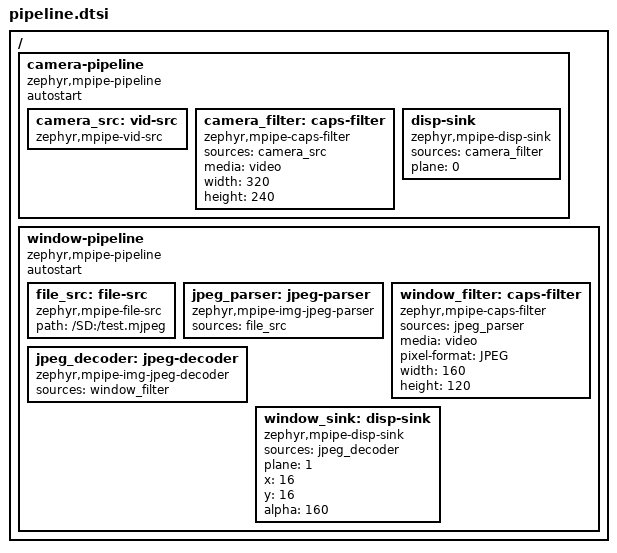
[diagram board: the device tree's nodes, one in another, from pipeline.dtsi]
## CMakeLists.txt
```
# Copyright 2026 NXP
# SPDX-License-Identifier: Apache-2.0

cmake_minimum_required(VERSION 3.20.0)
find_package(Zephyr REQUIRED HINTS $ENV{ZEPHYR_BASE})
project(pip_pipeline)

# The pipelines are described in pipeline.dtsi: the application only brings
# the file shown in the window
include(../common/mjpeg.cmake)
mpipe_sample_mjpeg_file(file_src window_filter)
```

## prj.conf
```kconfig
CONFIG_LOG=y

# The test file is written, then the pipelines built, on the main stack at boot
CONFIG_MAIN_STACK_SIZE=2048

# The framework, its elements and the players are enabled by the pipeline nodes
CONFIG_MPIPE_STRUCTURE_MAX_FIELDS=4
# One streaming thread per pipeline
CONFIG_MPIPE_THREADS_NUM=2
# Buffer headers in flight: the camera's frames (one on screen, one being
# captured, slack) plus the file chunks, every frame of a chunk cut as a view
# at once, and the decoded frames of the window
CONFIG_MPIPE_NET_BUF_POOL_COUNT=24
# Largest estimated size for a 320x240 JPEG image
CONFIG_MPIPE_IMG_JPEG_PARSER_MAX_FRAME_SIZE=153600
CONFIG_MPIPE_FS_BLOCK_SIZE=65536
CONFIG_MPIPE_FS_NUM_BUFS=4
# Decoded frames: one on screen, one being decoded
CONFIG_MPIPE_IMG_JPEG_DECODER_POOL_NUM=2

CONFIG_FILE_SYSTEM=y
CONFIG_FAT_FILESYSTEM_ELM=y
CONFIG_FS_FATFS_LFN=y
CONFIG_FS_FATFS_MAX_LFN=255
CONFIG_DISK_ACCESS=y
CONFIG_DISK_DRIVERS=y

# The bus carries end-of-stream and errors, never data: it needs neither
# zbus priority boost nor zbus logging of its own.
CONFIG_ZBUS_PRIORITY_BOOST=n
CONFIG_ZBUS_LOG_LEVEL_ERR=y
```

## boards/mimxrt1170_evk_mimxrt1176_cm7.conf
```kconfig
# Video buffers of every pool in the image: the camera's own queue, the frame
# kept on screen, the decoder's two output frames, slack
CONFIG_VIDEO_BUFFER_POOL_NUM_MAX=8
CONFIG_VIDEO_BUFFER_POOL_HEAP_SIZE=4194304

# The planes scan the pipelines' buffers out: no driver framebuffer
CONFIG_MCUX_LCDIFV2_FB_NUM=0
```

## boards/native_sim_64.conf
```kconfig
# A 160x120 JPEG frame is about 4.5 KB: a chunk holds the frames the parser
# cuts from it at once, bounded by the buffer headers above
CONFIG_MPIPE_FS_BLOCK_SIZE=32768

# Flash-backed FAT volume (disk-name "SD") for native_sim
CONFIG_FLASH_SIMULATOR=y
CONFIG_DISK_DRIVER_FLASH=y

# Bind the native PTY UART to stdin/stdout so the shell reads keystrokes typed
# on the launching terminal (otherwise the shell sits on a separate PTY and the
# p/s/r/q commands never receive input).
CONFIG_UART_NATIVE_PTY_0_ON_STDINOUT=y

# Log directly to stdout via the native backend, which is active from boot so
# the boot banner and early log lines (before the shell is up) are printed.
# Disable the shell log backend so those same lines are not printed a second
# time once the shell starts.
CONFIG_LOG_BACKEND_NATIVE_POSIX=y
CONFIG_SHELL_LOG_BACKEND=n

# Threads on native_sim run on host stacks, so this size is never used and
# only reserves memory.
CONFIG_MPIPE_PLAYER_WORKER_STACK_SIZE=64
```

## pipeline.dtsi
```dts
/*
 * Copyright 2026 NXP
 *
 * SPDX-License-Identifier: Apache-2.0
 */

#include "../common/sd_card.dtsi"

/ {
	/* The camera on the background plane of the display */
	camera-pipeline {
		compatible = "zephyr,mpipe-pipeline";
		autostart;

		camera_src: vid-src {
			compatible = "zephyr,mpipe-vid-src";
		};

		camera_filter: caps-filter {
			compatible = "zephyr,mpipe-caps-filter";
			sources = <&camera_src>;
			media = "video";
			width = <320>;
			height = <240>;
		};

		disp-sink {
			compatible = "zephyr,mpipe-disp-sink";
			sources = <&camera_filter>;
			plane = <0>;
		};
	};

	/* An MJPEG file in a translucent window, on a plane of its own */
	window-pipeline {
		compatible = "zephyr,mpipe-pipeline";
		autostart;

		file_src: file-src {
			compatible = "zephyr,mpipe-file-src";
			path = "/SD:/test.mjpeg";
		};

		jpeg_parser: jpeg-parser {
			compatible = "zephyr,mpipe-img-jpeg-parser";
			sources = <&file_src>;
		};

		window_filter: caps-filter {
			compatible = "zephyr,mpipe-caps-filter";
			sources = <&jpeg_parser>;
			media = "video";
			pixel-format = "JPEG";
			width = <160>;
			height = <120>;
		};

		jpeg_decoder: jpeg-decoder {
			compatible = "zephyr,mpipe-img-jpeg-decoder";
			sources = <&window_filter>;
		};

		window_sink: disp-sink {
			compatible = "zephyr,mpipe-disp-sink";
			sources = <&jpeg_decoder>;
			plane = <1>;
			x = <16>;
			y = <16>;
			alpha = <160>;
		};
	};
};
```

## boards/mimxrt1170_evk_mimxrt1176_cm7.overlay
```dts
/*
 * Copyright 2026 NXP
 *
 * SPDX-License-Identifier: Apache-2.0
 */

#include "../pipeline.dtsi"

/*
 * The camera frame is shown as captured, with no rotation stage, so it has to
 * fit the 720x1280 panel: 640x480 does, in portrait
 */
&camera_filter {
	width = <640>;
	height = <480>;
};

&window_filter {
	width = <320>;
	height = <240>;
};

&window_sink {
	x = <32>;
	y = <32>;
};
```

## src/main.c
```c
/*
 * Copyright 2026 NXP
 *
 * SPDX-License-Identifier: Apache-2.0
 */

#include <errno.h>
#include <ff.h>

#include <zephyr/drivers/display.h>
#include <zephyr/drivers/video.h>
#include <zephyr/fs/fs.h>
#include <zephyr/logging/log.h>

#include <zephyr/mpipe/mpipe.h>
#include <zephyr/mpipe/base/mpipe_caps_filter.h>
#include <zephyr/mpipe/disp/mpipe_disp_sink.h>
#include <zephyr/mpipe/fs/mpipe_file_src.h>
#include <zephyr/mpipe/img/mpipe_img_jpeg_decoder.h>
#include <zephyr/mpipe/img/mpipe_img_jpeg_parser.h>
#include <zephyr/mpipe/utils/mpipe_player.h>
#include <zephyr/mpipe/vid/mpipe_vid_src.h>

LOG_MODULE_REGISTER(main, CONFIG_LOG_DEFAULT_LEVEL);

/* Element IDs, unique within a pipeline; the pipeline id names the player */
enum {
	CAM_PIPE_ID,
	PIP_PIPE_ID,
	VID_SRC_ID,
	CAM_CAPS_FILTER_ID,
	CAM_DISP_SINK_ID,
	FILE_SRC_ID,
	JPEG_PARSER_ID,
	PIP_CAPS_FILTER_ID,
	JPEG_DEC_ID,
	PIP_DISP_SINK_ID,
};

#define MNT_POINT "/SD:"

static FATFS fat_fs;

static struct fs_mount_t mp = {
	.type = FS_FATFS,
	.fs_data = &fat_fs,
	.mnt_point = MNT_POINT,
};

static const uint8_t mjpeg[] = {
#include "mjpeg.inc"
};

/* Write the embedded MJPEG file to the volume unless it is already there */
static int embed_test_file(void)
{
	struct fs_dirent ent;
	struct fs_file_t f;
	ssize_t w;
	int ret = fs_stat(CONFIG_FILE_INPUT_PATH, &ent);

	if (ret == 0 && ent.size == sizeof(mjpeg)) {
		return 0;
	}
	if (ret != 0 && ret != -ENOENT) {
		LOG_ERR("fs_stat(%s) failed (%d)", CONFIG_FILE_INPUT_PATH, ret);
		return ret;
	}

	fs_file_t_init(&f);
	ret = fs_open(&f, CONFIG_FILE_INPUT_PATH, FS_O_CREATE | FS_O_WRITE | FS_O_TRUNC);
	if (ret != 0) {
		LOG_ERR("fs_open(%s) failed (%d)", CONFIG_FILE_INPUT_PATH, ret);
		return ret;
	}

	w = fs_write(&f, mjpeg, sizeof(mjpeg));
	(void)fs_close(&f);
	if (w < 0 || (size_t)w != sizeof(mjpeg)) {
		LOG_ERR("fs_write failed (%d)", (int)w);
		return (w < 0) ? (int)w : -EIO;
	}

	LOG_INF("Created %s (%u bytes)", CONFIG_FILE_INPUT_PATH, (unsigned int)sizeof(mjpeg));

	return 0;
}

/* The camera pipeline: vid_src -> caps_filter -> disp_sink on the camera plane */
static struct mpipe cam_pipe;

/* The window pipeline: file_src -> jpeg_parser -> caps_filter -> jpeg_decoder -> disp_sink */
static struct mpipe pip_pipe;

static int build_cam_pipeline(void)
{
	static struct mpipe_vid_src vid_src;
	static struct mpipe_caps_filter cam_caps_filter;
	static struct mpipe_disp_sink cam_disp_sink;
	static const int plane = CONFIG_VIDEO_PLANE;
	struct mpipe_structure caps;
	struct mpipe_value pixfmt;
	int ret;

	ret = mpipe_pipeline_init(&cam_pipe, CAM_PIPE_ID);
	if (ret < 0) {
		return ret;
	}
	ret = mpipe_vid_src_init(&vid_src, VID_SRC_ID);
	if (ret < 0) {
		return ret;
	}
	ret = mpipe_caps_filter_init(&cam_caps_filter, CAM_CAPS_FILTER_ID);
	if (ret < 0) {
		return ret;
	}
	ret = mpipe_disp_sink_init(&cam_disp_sink, CAM_DISP_SINK_ID);
	if (ret < 0) {
		return ret;
	}

	/* clang-format off */
	ret = mpipe_structure_init_fields(&caps, MPIPE_MEDIA_VIDEO,
		COND_CODE_0(CONFIG_VIDEO_FRAME_WIDTH,
			(), (MPIPE_CAPS_IMAGE_WIDTH, MPIPE_TYPE_UINT, CONFIG_VIDEO_FRAME_WIDTH,))
		COND_CODE_0(CONFIG_VIDEO_FRAME_HEIGHT,
			(), (MPIPE_CAPS_IMAGE_HEIGHT, MPIPE_TYPE_UINT, CONFIG_VIDEO_FRAME_HEIGHT,))
		MPIPE_CAPS_END);
	/* clang-format on */
	if (ret != 0) {
		return ret;
	}
	if (strcmp(CONFIG_VIDEO_PIXEL_FORMAT, "") != 0) {
		mpipe_value_set(&pixfmt, MPIPE_TYPE_UINT,
				VIDEO_FOURCC_FROM_STR(CONFIG_VIDEO_PIXEL_FORMAT));
		mpipe_structure_append_value(&caps, MPIPE_CAPS_PIXEL_FORMAT, &pixfmt);
	}
	ret = mpipe_object_set_properties((struct mpipe_object *)&cam_caps_filter,
					  MPIPE_PROP_BASE_CAPS_FILTER_CAPS, &caps,
					  MPIPE_PROP_LIST_END);
	if (ret < 0) {
		return ret;
	}

	ret = mpipe_object_set_properties((struct mpipe_object *)&cam_disp_sink,
					  MPIPE_PROP_DISP_SINK_PLANE, &plane, MPIPE_PROP_LIST_END);
	if (ret < 0) {
		return ret;
	}

	ret = mpipe_bin_add((struct mpipe_bin *)&cam_pipe, (struct mpipe_element *)&vid_src,
			    (struct mpipe_element *)&cam_caps_filter,
			    (struct mpipe_element *)&cam_disp_sink, NULL);
	if (ret < 0) {
		return ret;
	}

	return mpipe_element_link((struct mpipe_element *)&vid_src,
				  (struct mpipe_element *)&cam_caps_filter,
				  (struct mpipe_element *)&cam_disp_sink, NULL);
}

static int build_pip_pipeline(void)
{
	static struct mpipe_file_src file_src;
	static struct mpipe_img_jpeg_parser jpeg_parser;
	static struct mpipe_caps_filter pip_caps_filter;
	static struct mpipe_img_jpeg_decoder jpeg_dec;
	static struct mpipe_disp_sink pip_disp_sink;
	static const int plane = CONFIG_PIP_PLANE;
	static const uint16_t x = CONFIG_PIP_X;
	static const uint16_t y = CONFIG_PIP_Y;
	static const uint8_t alpha = CONFIG_PIP_ALPHA;
	struct mpipe_structure caps;
	int ret;

	ret = mpipe_pipeline_init(&pip_pipe, PIP_PIPE_ID);
	if (ret < 0) {
		return ret;
	}
	ret = mpipe_file_src_init(&file_src, FILE_SRC_ID);
	if (ret < 0) {
		return ret;
	}
	ret = mpipe_img_jpeg_parser_init(&jpeg_parser, JPEG_PARSER_ID);
	if (ret < 0) {
		return ret;
	}
	ret = mpipe_caps_filter_init(&pip_caps_filter, PIP_CAPS_FILTER_ID);
	if (ret < 0) {
		return ret;
	}
	ret = mpipe_img_jpeg_decoder_init(&jpeg_dec, JPEG_DEC_ID);
	if (ret < 0) {
		return ret;
	}
	ret = mpipe_disp_sink_init(&pip_disp_sink, PIP_DISP_SINK_ID);
	if (ret < 0) {
		return ret;
	}

	ret = mpipe_object_set_properties((struct mpipe_object *)&file_src, MPIPE_PROP_FS_SRC_PATH,
					  CONFIG_FILE_INPUT_PATH, MPIPE_PROP_LIST_END);
	if (ret < 0) {
		return ret;
	}

	ret = mpipe_structure_init_fields(
		&caps, MPIPE_MEDIA_VIDEO, MPIPE_CAPS_PIXEL_FORMAT, MPIPE_TYPE_UINT,
		VIDEO_PIX_FMT_JPEG, MPIPE_CAPS_IMAGE_WIDTH, MPIPE_TYPE_UINT,
		CONFIG_JPEG_IMAGE_WIDTH, MPIPE_CAPS_IMAGE_HEIGHT, MPIPE_TYPE_UINT,
		CONFIG_JPEG_IMAGE_HEIGHT, MPIPE_CAPS_END);
	if (ret != 0) {
		return ret;
	}
	ret = mpipe_object_set_properties((struct mpipe_object *)&pip_caps_filter,
					  MPIPE_PROP_BASE_CAPS_FILTER_CAPS, &caps,
					  MPIPE_PROP_LIST_END);
	if (ret < 0) {
		return ret;
	}

	/* The window: its own plane, placed over the camera frame, translucent */
	ret = mpipe_object_set_properties((struct mpipe_object *)&pip_disp_sink,
					  MPIPE_PROP_DISP_SINK_PLANE, &plane,
					  MPIPE_PROP_DISP_SINK_X, &x, MPIPE_PROP_DISP_SINK_Y, &y,
					  MPIPE_PROP_DISP_SINK_ALPHA, &alpha, MPIPE_PROP_LIST_END);
	if (ret < 0) {
		return ret;
	}

	ret = mpipe_bin_add(
		(struct mpipe_bin *)&pip_pipe, (struct mpipe_element *)&file_src,
		(struct mpipe_element *)&jpeg_parser, (struct mpipe_element *)&pip_caps_filter,
		(struct mpipe_element *)&jpeg_dec, (struct mpipe_element *)&pip_disp_sink, NULL);
	if (ret < 0) {
		return ret;
	}

	return mpipe_element_link(
		(struct mpipe_element *)&file_src, (struct mpipe_element *)&jpeg_parser,
		(struct mpipe_element *)&pip_caps_filter, (struct mpipe_element *)&jpeg_dec,
		(struct mpipe_element *)&pip_disp_sink, NULL);
}

int main(void)
{
	static struct mpipe_player cam_player;
	static struct mpipe_player pip_player;
	int ret = fs_mount(&mp);

	if (ret != 0) {
		LOG_ERR("fs_mount failed (%d)", ret);
		goto err;
	}
	LOG_INF("SDCard mounted at %s", MNT_POINT);

	ret = embed_test_file();
	if (ret != 0) {
		goto err;
	}

	ret = build_cam_pipeline();
	if (ret < 0) {
		LOG_ERR("Failed to build the camera pipeline (%d)", ret);
		goto err;
	}
	ret = build_pip_pipeline();
	if (ret < 0) {
		LOG_ERR("Failed to build the window pipeline (%d)", ret);
		goto err;
	}
	LOG_INF("Pipelines linked.");

	ret = mpipe_player_init(&cam_player, &cam_pipe);
	if (ret != 0) {
		LOG_ERR("Failed to init the camera player (%d)", ret);
		goto err;
	}
	ret = mpipe_player_init(&pip_player, &pip_pipe);
	if (ret != 0) {
		LOG_ERR("Failed to init the window player (%d)", ret);
		goto err;
	}

	(void)mpipe_player_play(&cam_player);
	(void)mpipe_player_play(&pip_player);
	(void)mpipe_player_wait_quit(&cam_player);
	(void)mpipe_player_wait_quit(&pip_player);
	(void)mpipe_player_deinit(&cam_player);
	(void)mpipe_player_deinit(&pip_player);

	ret = fs_unmount(&mp);
	if (ret != 0) {
		LOG_ERR("fs_unmount failed (%d)", ret);
	}

	LOG_INF("Done.");

	return 0;

err:
	LOG_ERR("Aborting sample");
	return 0;
}
```
